# RK3399-AP register map
File version: 1
CPU: CA7 r0p1, little endian, MPU, FPU, I-cache, D-cache, VTOR, 4 interrupt priority bits, 32 interrupts
Registers are 32-bit, read-write, reset 0x0 unless marked. A register's access mark holds for its fields unless they carry their own. Offsets are from the block's base; [hi:lo] are bit positions; {n}, {i} and the like mark numbered series; 'fields as' and 'values as' point back to an identical list.

## PMU
Base 0xFF310000
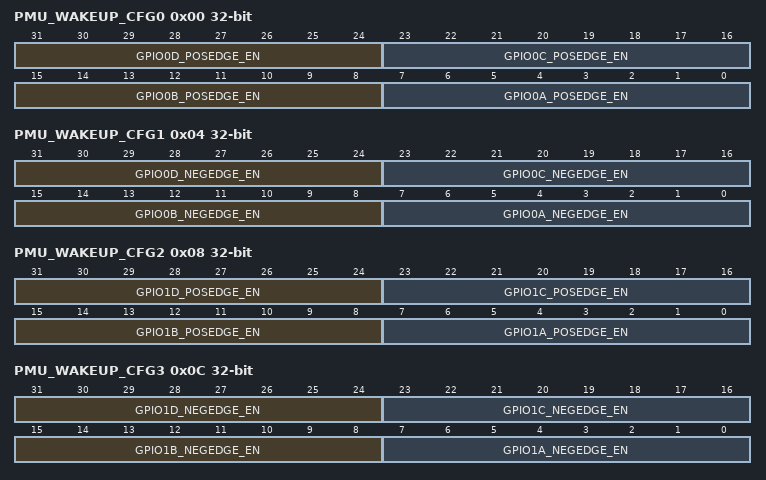
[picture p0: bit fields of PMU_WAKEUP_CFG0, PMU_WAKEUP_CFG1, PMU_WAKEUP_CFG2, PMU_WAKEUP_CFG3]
0x00 PMU_WAKEUP_CFG0 — pmu wakeup configure register 0
  [31:24] GPIO0D_POSEDGE_EN — gpio0d posedge pulse wakeup enable 0: disable 1: enable
  [23:16] GPIO0C_POSEDGE_EN — gpio0c posedge pulse wakeup enable 0: disable 1: enable
  [15:8] GPIO0B_POSEDGE_EN — gpio0b posedge pulse wakeup enable 0: disable 1: enable
  [7:0] GPIO0A_POSEDGE_EN — gpio0a posedge pulse wakeup enable 0: disable 1: enable
0x04 PMU_WAKEUP_CFG1 — pmu wakeup configure register 1
  [31:24] GPIO0D_NEGEDGE_EN — gpio0d negedge pulse wakeup enable 0: disable 1: enable
  [23:16] GPIO0C_NEGEDGE_EN — gpio0c negedge pulse wakeup enable 0: disable 1: enable
  [15:8] GPIO0B_NEGEDGE_EN — gpio0b negedge pulse wakeup enable 0: disable 1: enable
  [7:0] GPIO0A_NEGEDGE_EN — gpio0a negedge pulse wakeup enable 0: disable 1: enable
0x08 PMU_WAKEUP_CFG2 — pmu wakeup configure register 2
  [31:24] GPIO1D_POSEDGE_EN — gpio1d posedge pulse wakeup enable 0: disable 1: enable
  [23:16] GPIO1C_POSEDGE_EN — gpio1c posedge pulse wakeup enable 0: disable 1: enable
  [15:8] GPIO1B_POSEDGE_EN — gpio1b posedge pulse wakeup enable 0: disable 1: enable
  [7:0] GPIO1A_POSEDGE_EN — gpio1a posedge pulse wakeup enable 0: disable 1: enable
0x0C PMU_WAKEUP_CFG3 — pmu wakeup configure register 3
  [31:24] GPIO1D_NEGEDGE_EN — gpio1d negedge pulse wakeup enable 0: disable 1: enable
  [23:16] GPIO1C_NEGEDGE_EN — gpio1c negedge pulse wakeup enable 0: disable 1: enable
  [15:8] GPIO1B_NEGEDGE_EN — gpio1b negedge pulse wakeup enable 0: disable 1: enable
  [7:0] GPIO1A_NEGEDGE_EN — gpio1a negedge pulse wakeup enable 0: disable 1: enable
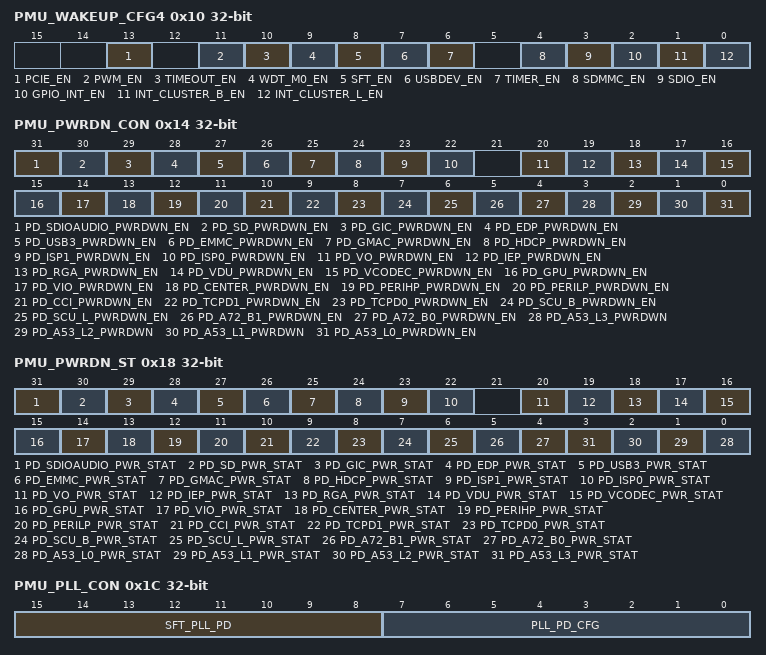
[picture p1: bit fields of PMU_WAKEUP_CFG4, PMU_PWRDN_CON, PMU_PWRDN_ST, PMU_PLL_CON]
0x10 PMU_WAKEUP_CFG4 — pmu wakeup configure register 4
  [13] PCIE_EN — pcie interrupt wakeup enable 0: disable 1: enable
  [11] PWM_EN — pwm interrupt wakeup enable 0: disable 1: enable
  [10] TIMEOUT_EN — pmu time out wakeup enable 0: disable 1: enable
  [9] WDT_M0_EN — m3 watch dog wakeup enable 0: disable 1: enable
  [8] SFT_EN — software wakeup enable 0: disable 1: enable
  [7] USBDEV_EN — usb device detect wakeup enable 0: disable 1: enable
  [6] TIMER_EN — timer wakeup enable 0: disable 1: enable
  [4] SDMMC_EN — sdmmc detect wakeup enable 0: disable 1: enable
  [3] SDIO_EN — sdio detect wakeup enable 0: disable 1: enable
  [2] GPIO_INT_EN — gpio interrupt wakeup enable 0: disable 1: enable
  [1] INT_CLUSTER_B_EN — cluster_b interrupt wakeup enable 0: disable 1: enable
  [0] INT_CLUSTER_L_EN — cluster_l interrupt wakeup enable 0: disable 1: enable
0x14 PMU_PWRDN_CON — pmu power down configure register
  [31] PD_SDIOAUDIO_PWRDWN_EN — pd_sdioaudio power down enable 0: disable 1: enable
  [30] PD_SD_PWRDWN_EN — pd_sd power down enable 0: disable 1: enable
  [29] PD_GIC_PWRDWN_EN — pd_gic power down enable 0: disable 1: enable
  [28] PD_EDP_PWRDWN_EN — pd_edp power down enable 0: disable 1: enable
  [27] PD_USB3_PWRDWN_EN — pd_usb3 power down enable 0: disable 1: enable
  [26] PD_EMMC_PWRDWN_EN — pd_emmc power down enable 0: disable 1: enable
  [25] PD_GMAC_PWRDWN_EN — pd_gmac power down enable 0: disable 1: enable
  [24] PD_HDCP_PWRDWN_EN — pd_hdcp power down enable 0: disable 1: enable
  [23] PD_ISP1_PWRDWN_EN — pd_isp1 power down enable 0: disable 1: enable
  [22] PD_ISP0_PWRDWN_EN — pd_isp0 power down enable 0: disable 1: enable
  [20] PD_VO_PWRDWN_EN — pd_vo power down enable 0: disable 1: enable
  [19] PD_IEP_PWRDWN_EN — pd_perihp power down enable 0: disable 1: enable
  [18] PD_RGA_PWRDWN_EN — pd_rga power down enable 0: disable 1: enable
  [17] PD_VDU_PWRDWN_EN — pd_vdu power down enable 0: disable 1: enable
  [16] PD_VCODEC_PWRDWN_EN — pd_perihp power down enable 0: disable 1: enable
  [15] PD_GPU_PWRDWN_EN — pd_gpu power down enable 0: disable 1: enable
  [14] PD_VIO_PWRDWN_EN — pd_vio power down enable 0: disable 1: enable
  [13] PD_CENTER_PWRDWN_EN — pd_center power down enable 0: disable 1: enable
  [12] PD_PERIHP_PWRDWN_EN — pd_perihp power down enable 0: disable 1: enable
  [11] PD_PERILP_PWRDWN_EN — pd_perilp power down enable 0: disable 1: enable
  [10] PD_CCI_PWRDWN_EN — pd_cci power down enable 0: disable 1: enable
  [9] PD_TCPD1_PWRDWN_EN — pd_tcpd1 power down enable 0: disable 1: enable
  [8] PD_TCPD0_PWRDWN_EN — pd_tcpd0 power down enable 0: disable 1: enable
  [7] PD_SCU_B_PWRDWN_EN — pd_scu_b power down enable 0: disable 1: enable
  [6] PD_SCU_L_PWRDWN_EN — pd_scu_l power down enable 0: disable 1: enable
  [5] PD_A72_B1_PWRDWN_EN — pd_a72_b0 power down enable 0: disable 1: enable
  [4] PD_A72_B0_PWRDWN_EN — pd_a72_b0 power down enable 0: disable 1: enable
  [3] PD_A53_L3_PWRDWN — pd_a53_l3 power down enable 0: disable 1: enable
  [2] PD_A53_L2_PWRDWN — pd_a53_l2 power down enable 0: disable 1: enable
  [1] PD_A53_L1_PWRDWN — pd_a53_l1 power down enable 0: disable 1: enable
  [0] PD_A53_L0_PWRDWN_EN — pd_a53_l0 power down enable 0: disable 1: enable
0x18 PMU_PWRDN_ST access per field — pmu power down status register
  [31] PD_SDIOAUDIO_PWR_STAT rw — pd_sdioaudio power state 0: powered up 1: powered down
  [30] PD_SD_PWR_STAT rw — pd_sd power state 0: powered up 1: powered down
  [29] PD_GIC_PWR_STAT rw — pd_gic power state 0: powered up 1: powered down
  [28] PD_EDP_PWR_STAT rw — pd_edp power state 0: powered up 1: powered down
  [27] PD_USB3_PWR_STAT rw — pd_usb3 power state 0: powered up 1: powered down
  [26] PD_EMMC_PWR_STAT rw — pd_emmc power state 0: powered up 1: powered down
  [25] PD_GMAC_PWR_STAT rw — pd_gmac power state 0: powered up 1: powered down
  [24] PD_HDCP_PWR_STAT rw — pd_hdcp power state 0: powered up 1: powered down
  [23] PD_ISP1_PWR_STAT rw — pd_isp1 power state 0: powered up 1: powered down
  [22] PD_ISP0_PWR_STAT rw — pd_isp0 power state 0: powered up 1: powered down
  [20] PD_VO_PWR_STAT rw — pd_vo power state 0: powered up 1: powered down
  [19] PD_IEP_PWR_STAT rw — pd_iep power state 0: powered up 1: powered down
  [18] PD_RGA_PWR_STAT rw — pd_rga power state 0: powered up 1: powered down
  [17] PD_VDU_PWR_STAT rw — pd_vdu power state 0: powered up 1: powered down
  [16] PD_VCODEC_PWR_STAT rw — pd_vcodec power state 0: powered up 1: powered down
  [15] PD_GPU_PWR_STAT rw — pd_gpu power state 0: powered up 1: powered down
  [14] PD_VIO_PWR_STAT rw — pd_vio power state 0: powered up 1: powered down
  [13] PD_CENTER_PWR_STAT rw — pd_center power state 0: powered up 1: powered down
  [12] PD_PERIHP_PWR_STAT rw — pd_peri power state 0: powered up 1: powered down
  [11] PD_PERILP_PWR_STAT rw — pd_bus power stat 0: powered up 1: powered down
  [10] PD_CCI_PWR_STAT rw — pd_core power state 0: powered up 1: powered down
  [9] PD_TCPD1_PWR_STAT rw — pd_tcpd1 power state 0: powered up 1: powered down
  [8] PD_TCPD0_PWR_STAT rw — pd_tcpd0 power state 0: powered up 1: powered down
  [7] PD_SCU_B_PWR_STAT ro — pd_scu_b power state 0: powered up 1: powered down
  [6] PD_SCU_L_PWR_STAT ro — pd_scu_l power state 0: powered up 1: powered down
  [5] PD_A72_B1_PWR_STAT ro — pd_a72_b1 power state 0: powered up 1: powered down
  [4] PD_A72_B0_PWR_STAT ro — pd_a72_b0 power state 0: powered up 1: powered down
  [n] PD_A53_L{n}_PWR_STAT ro (n=0..3) — pd_a53_l{n} power state 0: powered up 1: powered down
0x1C PMU_PLL_CON — PLL low power control register
  [15:8] SFT_PLL_PD — pll power down configured by sftware.
  [7:0] PLL_PD_CFG — pll power down configured by hardware
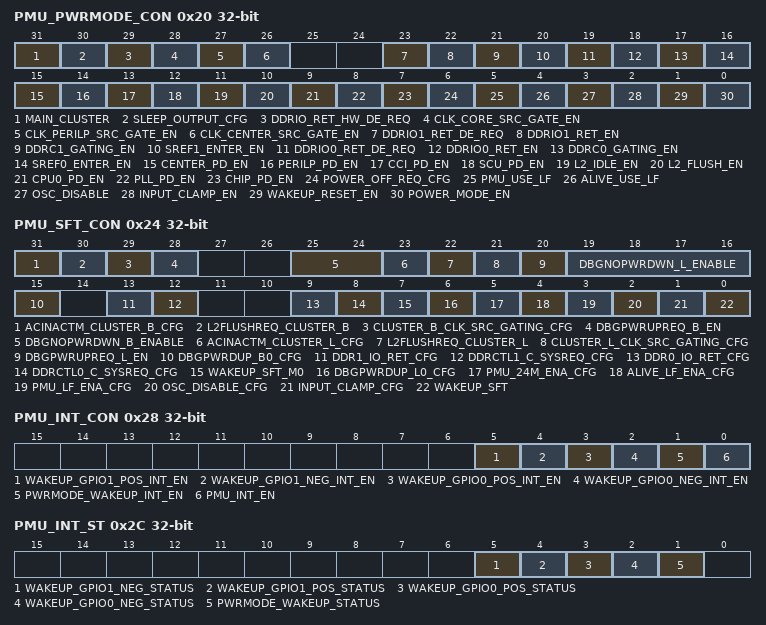
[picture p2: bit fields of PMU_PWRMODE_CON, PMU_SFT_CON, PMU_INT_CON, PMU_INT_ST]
0x20 PMU_PWRMODE_CON — pmu power mode configure register of common resource
  [31] MAIN_CLUSTER — use core big for main cluster. 0: core_l ; 1: core_b.
  [30] SLEEP_OUTPUT_CFG — output pmu_sleep instead of ap_pwroff to IO.
  [29] DDRIO_RET_HW_DE_REQ — hardware ddrio retention de-assert request
  [28] CLK_CORE_SRC_GATE_EN — cpu clock gate enable when in power mode 0: disable 1: enable
  [27] CLK_PERILP_SRC_GATE_EN — pd_perilp clock gate enable when in power mode 0: disable 1: enable
  [26] CLK_CENTER_SRC_GATE_EN — pd_center clock gate enable when in power mode 0: disable 1: enable
  [23] DDRIO1_RET_DE_REQ write-1-clears — ddrio1 retention de-assert request write one clear
  [22] DDRIO1_RET_EN — ddrio1 retention enable when in power mode 0: disable 1: enable
  [21] DDRC1_GATING_EN — ddr1 controller auto gating when in power mode 0: disable 1: enable
  [20] SREF1_ENTER_EN — ddr1 self_refresh by hardware when in power mode 0: disable 1: enable
  [19] DDRIO0_RET_DE_REQ write-1-clears — ddrio0 retention de-assert request write one clear
  [18] DDRIO0_RET_EN — ddrio0 retention enable when in power mode 0: disable 1: enable
  [17] DDRC0_GATING_EN — ddr0 controller auto gating when in power mode 0: disable 1: enable
  [16] SREF0_ENTER_EN — ddr0 self_refresh by hardware when in power mode 0: disable 1: enable
  [15] CENTER_PD_EN — power down pd_center when power mode 0: disable 1: enable
  [14] PERILP_PD_EN — power down pd_perilp when power mode 0: disable 1: enable
  [13] CCI_PD_EN — power down pd_cci when power mode 0: disable 1: enable
  [12] SCU_PD_EN — power down main cluster scu when in power mode 0: disable 1: enable
  [11] L2_IDLE_EN — wait l2 idle when in power mode 0: disable 1: enable
  [10] L2_FLUSH_EN — flush l2 by hardware when in power mode 0: disable 1: enable
  [9] CPU0_PD_EN — power down core0 of cluster_l in power mode 0: disable 1: enable
  [8] PLL_PD_EN — power down pll when in power mode 0: disable 1: enable
  [7] CHIP_PD_EN — chip power down enable 0: disable 1: enable
  [6] POWER_OFF_REQ_CFG — send power off request to PMIC when in power mode 0: disable 1: enable
  [5] PMU_USE_LF — pmu low frequency mode enable when in power mode 0: disable 1: enable
  [4] ALIVE_USE_LF — alive low frequency mode when in power mode 0: disable 1: enable
  [3] OSC_DISABLE — osc disable when in power mode 1: disable 0: enable
  [2] INPUT_CLAMP_EN — clamp vd_logic when in power mode 0: disable 1: enable
  [1] WAKEUP_RESET_EN — wakeup reset enable when in power mode 0: disable 1: enable
  [0] POWER_MODE_EN — enter power mode enable, will auto self-clear when in power mode 0: disable 1: enable
0x24 PMU_SFT_CON — pmu software configure register
  [31] ACINACTM_CLUSTER_B_CFG — acinactm indicate to cluster_b 0: acinactm to cluster_b is 0 1: acinactm to cluster_b is 1
  [30] L2FLUSHREQ_CLUSTER_B — send l2 flush request to cluster_l by software 0: disable 1: enable
  [29] CLUSTER_B_CLK_SRC_GATING_CFG — cluster_b clock source gating configure 0: disable 1: enable
  [28] DBGPWRUPREQ_B_EN — dbg powered up request function of cluster_b enable 0: disable 1: enable
  [25:24] DBGNOPWRDWN_B_ENABLE — dbgnopowerdown function of cluster_b enable 0: disable 1: enable
  [23] ACINACTM_CLUSTER_L_CFG — acinactm indicate to cluster_l 0: acinactm to cluster_l is 0 1: acinactm to cluster_l is 1
  [22] L2FLUSHREQ_CLUSTER_L — send l2 flush request to cluster_l by software 0: disable 1: enable
  [21] CLUSTER_L_CLK_SRC_GATING_CFG — cluster_l clock source gating configure 0: disable 1: enable
  [20] DBGPWRUPREQ_L_EN — dbg powered up request function of cluster_l enable 0: disable 1: enable
  [19:16] DBGNOPWRDWN_L_ENABLE — dbgnopowerdown function of cluster_l enable 0: disable 1: enable
  [15] DBGPWRDUP_B0_CFG — dbg powered up of pd_a72_b0 enable when in power mode 0: disable 1: enable
  [13] DDR1_IO_RET_CFG — ddr1 io retention configure by software 0: disable 1: enable
  [12] DDRCTL1_C_SYSREQ_CFG — ddrctl1 idle request configure 0: disable 1: enable
  [9] DDR0_IO_RET_CFG — ddr0 io retention configure by software 0: disable 1: enable
  [8] DDRCTL0_C_SYSREQ_CFG — ddrctl idle request configure 0: disable 1: enable
  [7] WAKEUP_SFT_M0 — m0 configure this bit to wakeup PMU state machine.
  [6] DBGPWRDUP_L0_CFG — dbg powered up of pd_a53_l0 enable when in power mode 0: disable 1: enable
  [5] PMU_24M_ENA_CFG — configure PD_PMU use 24M clock
  [4] ALIVE_LF_ENA_CFG — pd_alive low frequency mode configure by software 0: disable 1: enable
  [3] PMU_LF_ENA_CFG — pd_pmu low frequency mode configure by software 0: disable 1: enable
  [2] OSC_DISABLE_CFG — osc disable configure by software 1: disable osc 0: enable psc
  [1] INPUT_CLAMP_CFG — software control of input clamp signal
  [0] WAKEUP_SFT — software wakeup request bit A 0 to 1 pulse posedge will wakeup pmu when in low power mode
0x28 PMU_INT_CON — pmu interrupt configure register
  [5] WAKEUP_GPIO1_POS_INT_EN — gpio1 posedge wakeup interrupt enable 0: disable 1: enable
  [4] WAKEUP_GPIO1_NEG_INT_EN — gpio1 negedge wakeup interrupt enable 0: disable 1: enable
  [3] WAKEUP_GPIO0_POS_INT_EN — gpio posedge wakeup interrupt enable 0: disable 1: enable
  [2] WAKEUP_GPIO0_NEG_INT_EN — gpio0 negedge wakeup interrupt enable 0: disable 1: enable
  [1] PWRMODE_WAKEUP_INT_EN — power mode wakeup interrupt enable 0: disable 1: enable
  [0] PMU_INT_EN — global interrupt enable 0: disable 1: enable
0x2C PMU_INT_ST — pmu interrupt status register
  [5] WAKEUP_GPIO1_NEG_STATUS — gpio1 negedge pulse wakeup status 0: not wakeup by gpio1 negedge pulse 1: wakeup by gpio1 negedge pulse
  [4] WAKEUP_GPIO1_POS_STATUS — gpio1 posedge pulse wakeup status 0: not wakeup by gpio1 posedge pulse 1: wakeup by gpio1 posedge pulse
  [3] WAKEUP_GPIO0_POS_STATUS — gpio0 posedge pulse wakeup status 0: not wakeup by gpio0 posedge pulse 1: wakeup by gpio0 posedge pulse
  [2] WAKEUP_GPIO0_NEG_STATUS — gpio0 negedge pulse wakeup status 0: not wakeup by gpio negedge pulse 1: wakeup by gpio negedge pulse
  [1] PWRMODE_WAKEUP_STATUS — power mode wakeup status 0: not wakeup from power mode 1: wakeup from power mode
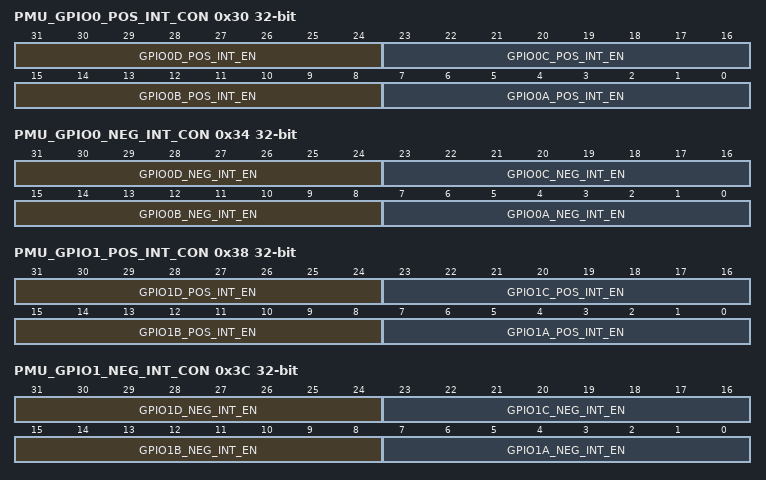
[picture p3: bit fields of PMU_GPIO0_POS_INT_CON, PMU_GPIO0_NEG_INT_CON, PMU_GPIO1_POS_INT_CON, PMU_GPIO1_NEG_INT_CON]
0x30 PMU_GPIO0_POS_INT_CON — pmu gpio0 posedge interrupt configure register
  [31:24] GPIO0D_POS_INT_EN — gpio0d posedge pulse interrupt enable 0: disable 1: enable
  [23:16] GPIO0C_POS_INT_EN — gpio0c posedge pulse interrupt enable 0: disable 1: enable
  [15:8] GPIO0B_POS_INT_EN — gpio0b posedge pulse interrupt enable 0: disable 1: enable
  [7:0] GPIO0A_POS_INT_EN — gpio0a posedge pulse interrupt enable 0: disable 1: enable
0x34 PMU_GPIO0_NEG_INT_CON — pmu gpio0 negedge interrupt configure register
  [31:24] GPIO0D_NEG_INT_EN — gpio0d negedge pulse interrupt enable 0: disable 1: enable
  [23:16] GPIO0C_NEG_INT_EN — gpio0c negedge pulse interrupt enable 0: disable 1: enable
  [15:8] GPIO0B_NEG_INT_EN — gpio0b negedge pulse interrupt enable 0: disable 1: enable
  [7:0] GPIO0A_NEG_INT_EN — gpio0a negedge pulse interrupt enable 0: disable 1: enable
0x38 PMU_GPIO1_POS_INT_CON — pmu gpio1 posedge interrupt configure register
  [31:24] GPIO1D_POS_INT_EN — gpio1d posedge pulse interrupt enable 0: disable 1: enable
  [23:16] GPIO1C_POS_INT_EN — gpio1c posedge pulse interrupt enable 0: disable 1: enable
  [15:8] GPIO1B_POS_INT_EN — gpio1b posedge pulse interrupt enable 0: disable 1: enable
  [7:0] GPIO1A_POS_INT_EN — gpio1a posedge pulse interrupt enable 0: disable 1: enable
0x3C PMU_GPIO1_NEG_INT_CON — pmu gpio1 negedge interrupt configure register
  [31:24] GPIO1D_NEG_INT_EN — gpio1d negedge pulse interrupt enable 0: disable 1: enable
  [23:16] GPIO1C_NEG_INT_EN — gpio1c negedge pulse interrupt enable 0: disable 1: enable
  [15:8] GPIO1B_NEG_INT_EN — gpio1b negedge pulse interrupt enable 0: disable 1: enable
  [7:0] GPIO1A_NEG_INT_EN — gpio1a negedge pulse interrupt enable 0: disable 1: enable
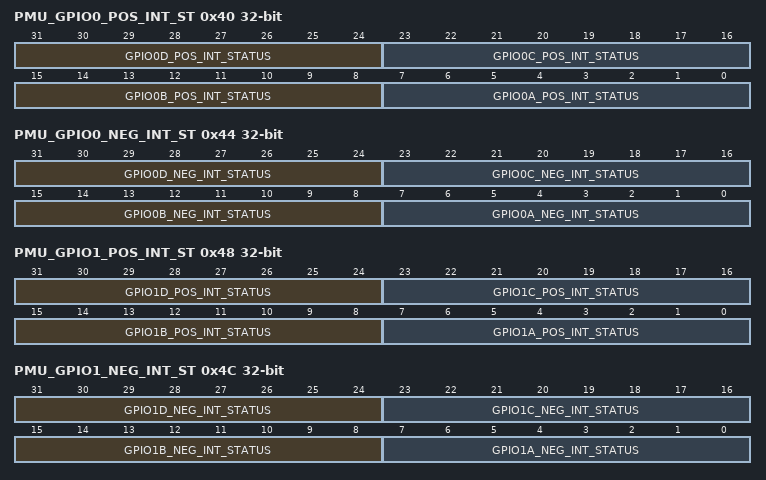
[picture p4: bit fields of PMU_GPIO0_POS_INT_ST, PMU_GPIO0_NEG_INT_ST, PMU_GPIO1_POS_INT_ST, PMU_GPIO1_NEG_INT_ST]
0x40 PMU_GPIO0_POS_INT_ST — pmu gpio0 posedge interrupt status register
  [31:24] GPIO0D_POS_INT_STATUS — gpio0d posedge pulse interrupt status 0: not wakeup by gpio0d posedge pulse 1: wakeup by gpio0d posedge pulse
  [23:16] GPIO0C_POS_INT_STATUS — gpio0c posedge pulse interrupt status 0: not wakeup by gpio0c posedge pulse 1: wakeup by gpio0c posedge pulse
  [15:8] GPIO0B_POS_INT_STATUS — gpio0b posedge pulse interrupt status 0: not wakeup by gpio0b posedge pulse 1: wakeup by gpio0b posedge pulse
  [7:0] GPIO0A_POS_INT_STATUS — gpio0a posedge pulse interrupt status 0: not wakeup by gpio0a posedge pulse 1: wakeup by gpio0a posedge pulse
0x44 PMU_GPIO0_NEG_INT_ST — pmu gpio0 negedge interrupt status register
  [31:24] GPIO0D_NEG_INT_STATUS — gpio0d negedge pulse interrupt status 0: not wakeup by gpio0d negedge pulse 1: wakeup by gpio0d negedge pulse
  [23:16] GPIO0C_NEG_INT_STATUS — gpio0c negedge pulse interrupt status 0: not wakeup by gpio0c negedge pulse 1: wakeup by gpio0c negedge pulse
  [15:8] GPIO0B_NEG_INT_STATUS — gpio0b negedge pulse interrupt status 0: not wakeup by gpio0b negedge pulse 1: wakeup by gpio0b negedge pulse
  [7:0] GPIO0A_NEG_INT_STATUS — gpio0a negedge pulse interrupt status 0: not wakeup by gpio0a negedge pulse 1: wakeup by gpio0a negedge pulse
0x48 PMU_GPIO1_POS_INT_ST — pmu gpio1 posedge interrupt status register
  [31:24] GPIO1D_POS_INT_STATUS — gpio1d posedge pulse interrupt status 0: not wakeup by gpio1d posedge pulse 1: wakeup by gpio1d posedge pulse
  [23:16] GPIO1C_POS_INT_STATUS — gpio1c posedge pulse interrupt status 0: not wakeup by gpio1c posedge pulse 1: wakeup by gpio1c posedge pulse
  [15:8] GPIO1B_POS_INT_STATUS — gpio1b posedge pulse interrupt status 0: not wakeup by gpio1b posedge pulse 1: wakeup by gpio1b posedge pulse
  [7:0] GPIO1A_POS_INT_STATUS — gpio1a posedge pulse interrupt status 0: not wakeup by gpio1a posedge pulse 1: wakeup by gpio1a posedge pulse
0x4C PMU_GPIO1_NEG_INT_ST — pmu gpio1 negedge interrupt status register
  [31:24] GPIO1D_NEG_INT_STATUS — gpio1d negedge pulse interrupt status 0: not wakeup by gpio1d negedge pulse 1: wakeup by gpio1d negedge pulse
  [23:16] GPIO1C_NEG_INT_STATUS — gpio1c negedge pulse interrupt status 0: not wakeup by gpio1c negedge pulse 1: wakeup by gpio1c negedge pulse
  [15:8] GPIO1B_NEG_INT_STATUS — gpio1b negedge pulse interrupt status 0: not wakeup by gpio1b negedge pulse 1: wakeup by gpio1b negedge pulse
  [7:0] GPIO1A_NEG_INT_STATUS — gpio1a negedge pulse interrupt status 0: not wakeup by gpio1a negedge pulse 1: wakeup by gpio1a negedge pulse
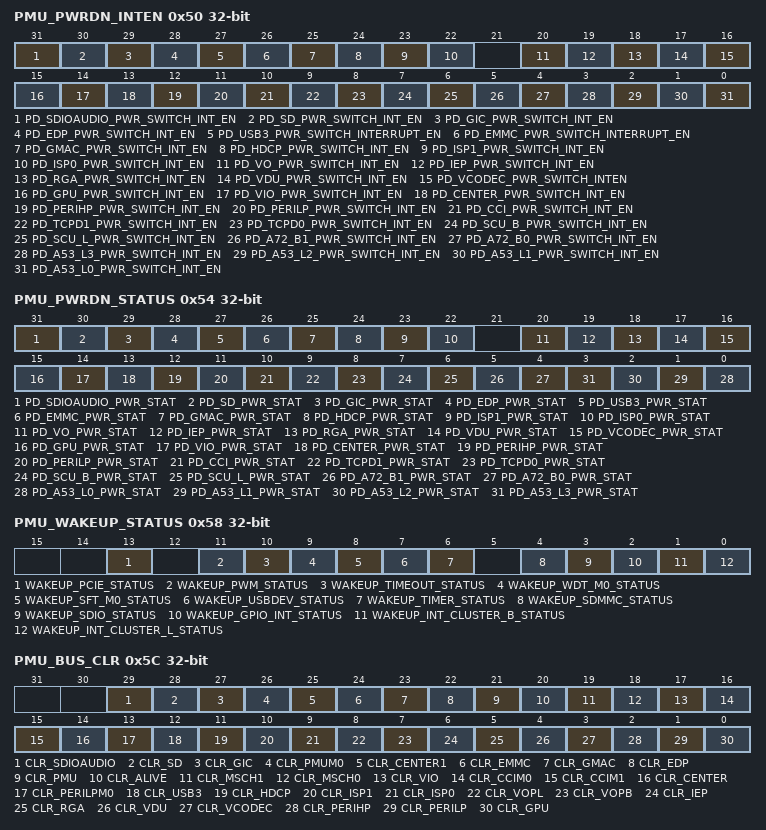
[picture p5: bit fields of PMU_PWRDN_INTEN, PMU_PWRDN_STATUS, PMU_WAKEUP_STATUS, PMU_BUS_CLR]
0x50 PMU_PWRDN_INTEN — pmu power down interrupt enable register/pmu power down configure register
  [31] PD_SDIOAUDIO_PWR_SWITCH_INT_EN — pd_sdioaudio power switch interrupt enable 0: disable 1: enable
  [30] PD_SD_PWR_SWITCH_INT_EN — pd_sd power switch interrupt enable 0: disable 1: enable
  [29] PD_GIC_PWR_SWITCH_INT_EN — pd_gic power switch interrupt enable 0: disable 1: enable
  [28] PD_EDP_PWR_SWITCH_INT_EN — pd_edp power switch interrupt enable 0: disable 1: enable
  [27] PD_USB3_PWR_SWITCH_INTERRUPT_EN — pd_usb3 power switch interrupt enable 0: disable 1: enable
  [26] PD_EMMC_PWR_SWITCH_INTERRUPT_EN — pd_emmc power switch interrupt enable 0: disable 1: enable
  [25] PD_GMAC_PWR_SWITCH_INT_EN — pd_gmac power switch interrupt enable 0: disable 1: enable
  [24] PD_HDCP_PWR_SWITCH_INT_EN — pd_hdcp power switch interrupt enable 0: disable 1: enable
  [23] PD_ISP1_PWR_SWITCH_INT_EN — pd_isp1 power switch interrupt enable 0: disable 1: enable
  [22] PD_ISP0_PWR_SWITCH_INT_EN — pd_isp0 power switch interrupt enable 0: disable 1: enable
  [20] PD_VO_PWR_SWITCH_INT_EN — pd_vo power switch interrupt enable 0: disable 1: enable
  [19] PD_IEP_PWR_SWITCH_INT_EN — pd_perihp power switch interrupt enable 0: disable 1: enable
  [18] PD_RGA_PWR_SWITCH_INT_EN — pd_rga power switch interrupt enable 0: disable 1: enable
  [17] PD_VDU_PWR_SWITCH_INT_EN — pd_vdu power switch interrupt enable 0: disable 1: enable
  [16] PD_VCODEC_PWR_SWITCH_INTEN — pd_perihp power switch interrupt enable 0: disable 1: enable
  [15] PD_GPU_PWR_SWITCH_INT_EN — pd_gpu power interrupt enable 0: disable 1: enable
  [14] PD_VIO_PWR_SWITCH_INT_EN — pd_vio power switch interrupt enable 0: disable 1: enable
  [13] PD_CENTER_PWR_SWITCH_INT_EN — pd_center power switch interrupt enable 0: disable 1: enable
  [12] PD_PERIHP_PWR_SWITCH_INT_EN — pd_perihp power switch interrupt enable 0: disable 1: enable
  [11] PD_PERILP_PWR_SWITCH_INT_EN — pd_perilp power switch interrupt enable 0: disable 1: enable
  [10] PD_CCI_PWR_SWITCH_INT_EN — pd_cci power switch interrupt enable 0: disable 1: enable
  [9] PD_TCPD1_PWR_SWITCH_INT_EN — pd_tcpd1 power switch interrupt enable 0: disable 1: enable
  [8] PD_TCPD0_PWR_SWITCH_INT_EN — pd_tcpd0 power switch interrupt enable 0: disable 1: enable
  [7] PD_SCU_B_PWR_SWITCH_INT_EN — pd_scu_b power switch interrupt enable 0: disable 1: enable
  [6] PD_SCU_L_PWR_SWITCH_INT_EN — pd_scu_l power switch interrupt enable 0: disable 1: enable
  [5] PD_A72_B1_PWR_SWITCH_INT_EN — pd_a72_b1 power switch interrupt enable 0: disable 1: enable
  [4] PD_A72_B0_PWR_SWITCH_INT_EN — pd_a72_b0 power enable 0: disable 1: enable
  [3] PD_A53_L3_PWR_SWITCH_INT_EN — pd_a53_l3 power switch int enable 0: disable 1: enable
  [2] PD_A53_L2_PWR_SWITCH_INT_EN — pd_a53_l2 power switch interrupt enable 0: disable 1: enable
  [1] PD_A53_L1_PWR_SWITCH_INT_EN — pd_a53_l1 power switch interrupt enable 0: disable 1: enable
  [0] PD_A53_L0_PWR_SWITCH_INT_EN — pd_a53_l0 power switch interrupt enable 0: disable 1: enable
0x54 PMU_PWRDN_STATUS — pmu power down interrupt status register/pmu power down status register
  [31] PD_SDIOAUDIO_PWR_STAT write-1-clears — pd_sdioaudio power state 0: powered up 1: powered down
  [30] PD_SD_PWR_STAT write-1-clears — pd_sd power state 0: powered up 1: powered down
  [29] PD_GIC_PWR_STAT write-1-clears — pd_gic power state 0: powered up 1: powered down
  [28] PD_EDP_PWR_STAT write-1-clears — pd_edp power state 0: powered up 1: powered down
  [27] PD_USB3_PWR_STAT write-1-clears — pd_usb3 power state 0: powered up 1: powered down
  [26] PD_EMMC_PWR_STAT write-1-clears — pd_emmc power state 0: powered up 1: powered down
  [25] PD_GMAC_PWR_STAT write-1-clears — pd_gmac power state 0: powered up 1: powered down
  [24] PD_HDCP_PWR_STAT write-1-clears — pd_hdcp power state 0: powered up 1: powered down
  [23] PD_ISP1_PWR_STAT write-1-clears — pd_isp1 power state 0: powered up 1: powered down
  [22] PD_ISP0_PWR_STAT write-1-clears — pd_isp0 power state 0: powered up 1: powered down
  [20] PD_VO_PWR_STAT write-1-clears — pd_vo power state 0: powered up 1: powered down
  [19] PD_IEP_PWR_STAT write-1-clears — pd_iep power state 0: powered up 1: powered down
  [18] PD_RGA_PWR_STAT write-1-clears — pd_rga power state 0: powered up 1: powered down
  [17] PD_VDU_PWR_STAT write-1-clears — pd_vdu power state 0: powered up 1: powered down
  [16] PD_VCODEC_PWR_STAT write-1-clears — pd_vcodec power state 0: powered up 1: powered down
  [15] PD_GPU_PWR_STAT write-1-clears — pd_gpu power state 0: powered up 1: powered down
  [14] PD_VIO_PWR_STAT write-1-clears — pd_vio power state 0: powered up 1: powered down
  [13] PD_CENTER_PWR_STAT write-1-clears — pd_center power state 0: powered up 1: powered down
  [12] PD_PERIHP_PWR_STAT write-1-clears — pd_perihp power state 0: powered up 1: powered down
  [11] PD_PERILP_PWR_STAT write-1-clears — pd_perilp power stat 0: powered up 1: powered down
  [10] PD_CCI_PWR_STAT write-1-clears — pd_core power state 0: powered up 1: powered down
  [9] PD_TCPD1_PWR_STAT write-1-clears — pd_tcpd1 power state 0: powered up 1: powered down
  [8] PD_TCPD0_PWR_STAT write-1-clears — pd_tcpd0 power state 0: powered up 1: powered down
  [7] PD_SCU_B_PWR_STAT write-1-clears — pd_scu_b power state 0: powered up 1: powered down
  [6] PD_SCU_L_PWR_STAT write-1-clears — pd_scu_l power state 0: powered up 1: powered down
  [5] PD_A72_B1_PWR_STAT write-1-clears — pd_a72_b1 power state 0: powered up 1: powered down
  [4] PD_A72_B0_PWR_STAT write-1-clears — pd_a72_b0 power state 0: powered up 1: powered down
  [n] PD_A53_L{n}_PWR_STAT write-1-clears (n=0..3) — pd_a53_l{n} power state 0: powered up 1: powered down
0x58 PMU_WAKEUP_STATUS — pmu interrupt wakeup status register/pmu interrupt status register
  [13] WAKEUP_PCIE_STATUS — pcie wakeup status 0: not wakeup by pcie 1: wakeup by pcie
  [11] WAKEUP_PWM_STATUS — pwm wakeup status 0: not wakeup by pwm 1: wakeup by pwm
  [10] WAKEUP_TIMEOUT_STATUS — timeout wakeup status 0: not wakeup by timeout 1: wakeup by timeout
  [9] WAKEUP_WDT_M0_STATUS — m0 wdt interrupt wakeup status 0: not wakeup by m0 wdt interrupt 1: wakeup by m0 wdt interrupt
  [8] WAKEUP_SFT_M0_STATUS — m0 software control wakeup status 0: not wakeup by software 1: wakeup by software
  [7] WAKEUP_USBDEV_STATUS — usbdev detect wakeup status 0: not wakeup by usbdev detect 1: wakeup by usbdev detect
  [6] WAKEUP_TIMER_STATUS — timer wakeup status 0: not wakeup by timer 1: wakeup by timer
  [4] WAKEUP_SDMMC_STATUS — sdmmc wakeup status 0: not wakeup by sdmmc detect 1: wakeup by sdmmc detect
  [3] WAKEUP_SDIO_STATUS — sdio wakeup status 0: not wakeup by sdio detect 1: wakeup by sdio detect
  [2] WAKEUP_GPIO_INT_STATUS — gpio interrupt wakeup status 0: not wakeup by gpio int 1: wakeup by gpio int
  [1] WAKEUP_INT_CLUSTER_B_STATUS — cluster_b interrupt wakeup status 0: not wakeup by interrupt cluster_b 1: wakeup by interrupt cluster_b
  [0] WAKEUP_INT_CLUSTER_L_STATUS — cluster_l interrupt wakeup status 0: not wakeup by interrupt cluster_l 1: wakeup by interrupt cluster_l
0x5C PMU_BUS_CLR — pmu bus clear register
  [29] CLR_SDIOAUDIO — send idle request to sdioaudio low power interface 0: disable 1: enable
  [28] CLR_SD — send idle request to sd low power interface 0: disable 1: enable
  [27] CLR_GIC — send idle request to gic low power interface 0: disable 1: enable
  [26] CLR_PMUM0 — send idle request to pmu m0 low power interface 0: disable 1: enable
  [25] CLR_CENTER1 — send idle request to center1 low power interface 0: disable 1: enable
  [24] CLR_EMMC — send idle request to emmc low power interface 0: disable 1: enable
  [23] CLR_GMAC — send idle request to gmac low power interface 0: disable 1: enable
  [22] CLR_EDP — send idle request to edp low power interface 0: disable 1: enable
  [21] CLR_PMU — send idle request to pmu low power interface 0: disable 1: enable
  [20] CLR_ALIVE — send idle request to alive low power interface 0: disable 1: enable
  [19] CLR_MSCH1 — send idle request to msch1 low power interface 0: disable 1: enable
  [18] CLR_MSCH0 — send idle request to msch0 low power interface 0: disable 1: enable
  [17] CLR_VIO — send idle request to vio low power interface 0: disable 1: enable
  [16] CLR_CCIM0 — send idle request to ccim0 low power interface 0: disable 1: enable
  [15] CLR_CCIM1 — send idle request to ccim1 low power interface 0: disable 1: enable
  [14] CLR_CENTER — send idle request to center niu 0: disable 1: enable
  [13] CLR_PERILPM0 — send idle request to perilp m0 niu 0: disable 1: enable
  [12] CLR_USB3 — send idle request to usb3 niu 0: disable 1: enable
  [11] CLR_HDCP — send idle request to hdcp niu 0: disable 1: enable
  [10] CLR_ISP1 — send idle request to isp1 niu 0: disable 1: enable
  [9] CLR_ISP0 — send idle request to isp0 niu 0: disable 1: enable
  [8] CLR_VOPL — send idle request to vopl niu 0: disable 1: enable
  [7] CLR_VOPB — send idle request to vopb niu 0: disable 1: enable
  [6] CLR_IEP — send idle request to iep niu 0: disable 1: enable
  [5] CLR_RGA — send idle request to rga niu 0: disable 1: enable
  [4] CLR_VDU — send idle request to vdu niu 0: disable 1: enable
  [3] CLR_VCODEC — send idle request to vcodec niu 0: disable 1: enable
  [2] CLR_PERIHP — send idle request to perihp niu 0: disable 1: enable
  [1] CLR_PERILP — send idle request to perilp niu 0: disable 1: enable
  [0] CLR_GPU — send idle request to gpu niu 0: disable 1: enable
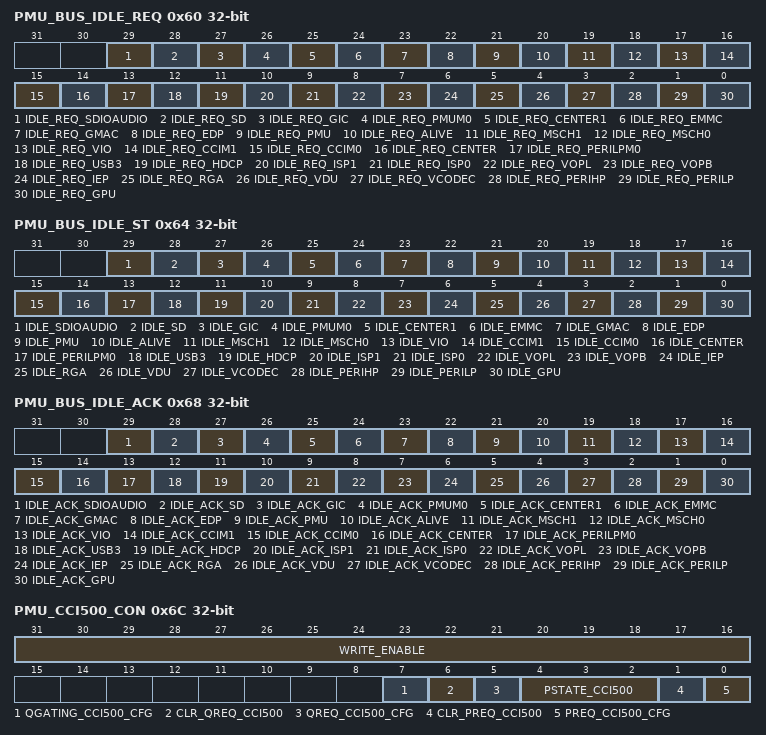
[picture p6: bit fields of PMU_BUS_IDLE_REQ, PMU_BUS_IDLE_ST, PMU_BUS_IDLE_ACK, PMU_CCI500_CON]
0x60 PMU_BUS_IDLE_REQ — pmu bus idle request register
  [29] IDLE_REQ_SDIOAUDIO — send idle request to sdioaudio low power interface 0: disable 1: enable
  [28] IDLE_REQ_SD — send idle request to sd low power interface 0: disable 1: enable
  [27] IDLE_REQ_GIC — send idle request to gic low power interface 0: disable 1: enable
  [26] IDLE_REQ_PMUM0 — send idle request to pmu m0 low power interface 0: disable 1: enable
  [25] IDLE_REQ_CENTER1 — send idle request to center1 low power interface 0: disable 1: enable
  [24] IDLE_REQ_EMMC — send idle request to emmc low power interface 0: disable 1: enable
  [23] IDLE_REQ_GMAC — send idle request to gmac low power interface 0: disable 1: enable
  [22] IDLE_REQ_EDP — send idle request to edp low power interface 0: disable 1: enable
  [21] IDLE_REQ_PMU — send idle request to pmu low power interface 0: disable 1: enable
  [20] IDLE_REQ_ALIVE — send idle request to alive low power interface 0: disable 1: enable
  [19] IDLE_REQ_MSCH1 — send idle request to msch1 low power interface 0: disable 1: enable
  [18] IDLE_REQ_MSCH0 — send idle request to msch0 low power interface 0: disable 1: enable
  [17] IDLE_REQ_VIO — send idle request to vio low power interface 0: disable 1: enable
  [16] IDLE_REQ_CCIM1 — send idle request to ccim1 low power interface 0: disable 1: enable
  [15] IDLE_REQ_CCIM0 — send idle request to ccim0 low power interface 0: disable 1: enable
  [14] IDLE_REQ_CENTER — send idle request to center niu 0: disable 1: enable
  [13] IDLE_REQ_PERILPM0 — send idle request to perilp m0 niu 0: disable 1: enable
  [12] IDLE_REQ_USB3 — send idle request to usb3 niu 0: disable 1: enable
  [11] IDLE_REQ_HDCP — send idle request to hdcp niu 0: disable 1: enable
  [10] IDLE_REQ_ISP1 — send idle request to isp1 niu 0: disable 1: enable
  [9] IDLE_REQ_ISP0 — send idle request to isp0 niu 0: disable 1: enable
  [8] IDLE_REQ_VOPL — send idle request to vopl niu 0: disable 1: enable
  [7] IDLE_REQ_VOPB — send idle request to vopb niu 0: disable 1: enable
  [6] IDLE_REQ_IEP — send idle request to iep niu 0: disable 1: enable
  [5] IDLE_REQ_RGA — send idle request to rga niu 0: disable 1: enable
  [4] IDLE_REQ_VDU — send idle request to vdu niu 0: disable 1: enable
  [3] IDLE_REQ_VCODEC — send idle request to vcodec niu 0: disable 1: enable
  [2] IDLE_REQ_PERIHP — send idle request to perihp niu 0: disable 1: enable
  [1] IDLE_REQ_PERILP — send idle request to perilp niu 0: disable 1: enable
  [0] IDLE_REQ_GPU — send idle request to gpu niu 0: disable 1: enable
0x64 PMU_BUS_IDLE_ST ro — pmu bus idle status register
  [29] IDLE_SDIOAUDIO — send idle request to sdioaudio low power interface 0: disable 1: enable
  [28] IDLE_SD — send idle request to sd low power interface 0: disable 1: enable
  [27] IDLE_GIC — idle status of gic niu 0: idle status of niu is 0 1: idle status of niu is 1
  [26] IDLE_PMUM0 — idle status of pmu m0 niu 0: idle status of niu is 0 1: idle status of niu is 1
  [25] IDLE_CENTER1 — idle status of center1 niu 0: idle status of niu is 0 1: idle status of niu is 1
  [24] IDLE_EMMC — idle status of emmc niu 0: idle status of niu is 0 1: idle status of niu is 1
  [23] IDLE_GMAC — idle status of gmac niu 0: idle status of niu is 0 1: idle status of niu is 1
  [22] IDLE_EDP — idle status of edp niu 0: idle status of niu is 0 1: idle status of niu is 1
  [21] IDLE_PMU — idle status of pmu niu 0: idle status of niu is 0 1: idle status of niu is 1
  [20] IDLE_ALIVE — idle status of alive niu 0: idle status of niu is 0 1: idle status of niu is 1
  [19] IDLE_MSCH1 — idle status of msch1 niu 0: idle status of niu is 0 1: idle status of niu is 1
  [18] IDLE_MSCH0 — idle status of msch0 niu 0: idle status of niu is 0 1: idle status of niu is 1
  [17] IDLE_VIO — idle status of vio niu 0: idle status of niu is 0 1: idle status of niu is 1
  [16] IDLE_CCIM1 — idle status of ccim1 niu 0: idle status of niu is 0 1: idle status of niu is 1
  [15] IDLE_CCIM0 — idle status of ccim0 niu 0: idle status of niu is 0 1: idle status of niu is 1
  [14] IDLE_CENTER — idle status of center niu 0: idle status of niu is 0 1: idle status of niu is 1
  [13] IDLE_PERILPM0 — idle status of perilpm0 niu 0: idle status of niu is 0 1: idle status of niu is 1
  [12] IDLE_USB3 — idle status of usb3 niu 0: idle status of niu is 0 1: idle status of niu is 1
  [11] IDLE_HDCP — idle status of hdcp niu 0: idle status of niu is 0 1: idle status of niu is 1
  [10] IDLE_ISP1 — idle status of isp1 niu 0: idle status of niu is 0 1: idle status of niu is 1
  [9] IDLE_ISP0 — idle status of isp0 niu 0: idle status of niu is 0 1: idle status of niu is 1
  [8] IDLE_VOPL — idle status of vopl niu 0: idle status of niu is 0 1: idle status of niu is 1
  [7] IDLE_VOPB — idle status of vopb niu 0: idle status of niu is 0 1: idle status of niu is 1
  [6] IDLE_IEP — idle status of iep niu 0: idle status of niu is 0 1: idle status of niu is 1
  [5] IDLE_RGA — idle status of rga niu 0: idle status of niu is 0 1: idle status of niu is 1
  [4] IDLE_VDU — idle status of vdu niu 0: idle status of niu is 0 1: idle status of niu is 1
  [3] IDLE_VCODEC — idle status of vcodec niu 0: idle status of niu is 0 1: idle status of niu is 1
  [2] IDLE_PERIHP — idle status of perihp niu 0: idle status of niu is 0 1: idle status of niu is 1
  [1] IDLE_PERILP — idle status of perilp niu 0: idle status of niu is 0 1: idle status of niu is 1
  [0] IDLE_GPU — idle status of gpu niu 0: idle status of gpu_niu is 0 1: idle status of gpu_niu is 1
0x68 PMU_BUS_IDLE_ACK ro — pmu bus idle ack status register
  [29] IDLE_ACK_SDIOAUDIO — idle acknowledge status from sdioaudio niu 0: idle acknowledge status of niu is 0 1: idle acknowledge status of niu is 1
  [28] IDLE_ACK_SD — idle acknowledge status from sd niu 0: idle acknowledge status of niu is 0 1: idle acknowledge status of niu is 1
  [27] IDLE_ACK_GIC — idle acknowledge status from gic niu 0: idle acknowledge status of niu is 0 1: idle acknowledge status of niu is 1
  [26] IDLE_ACK_PMUM0 — idle acknowledge status from pmu m0 niu 0: idle acknowledge status of niu is 0 1: idle acknowledge status of niu is 1
  [25] IDLE_ACK_CENTER1 — idle acknowledge status from center1 niu 0: idle acknowledge status of niu is 0 1: idle acknowledge status of niu is 1
  [24] IDLE_ACK_EMMC — idle acknowledge status from emmc niu 0: idle acknowledge status of niu is 0 1: idle acknowledge status of niu is 1
  [23] IDLE_ACK_GMAC — idle acknowledge status from gmac niu 0: idle acknowledge status of niu is 0 1: idle acknowledge status of niu is 1
  [22] IDLE_ACK_EDP — idle acknowledge status from edp niu 0: idle acknowledge status of niu is 0 1: idle acknowledge status of niu is 1
  [21] IDLE_ACK_PMU — idle acknowledge status from pmu niu 0: idle acknowledge status of niu is 0 1: idle acknowledge status of niu is 1
  [20] IDLE_ACK_ALIVE — idle acknowledge status from alive niu 0: idle acknowledge status of niu is 0 1: idle acknowledge status of niu is 1
  [19] IDLE_ACK_MSCH1 — idle acknowledge status from msch1 niu 0: idle acknowledge status of niu is 0 1: idle acknowledge status of niu is 1
  [18] IDLE_ACK_MSCH0 — idle acknowledge status from msch0 niu 0: idle acknowledge status of niu is 0 1: idle acknowledge status of niu is 1
  [17] IDLE_ACK_VIO — idle acknowledge status from vio niu 0: idle acknowledge status of niu is 0 1: idle acknowledge status of niu is 1
  [16] IDLE_ACK_CCIM1 — idle acknowledge status from ccim1 niu 0: idle acknowledge status of niu is 0 1: idle acknowledge status of niu is 1
  [15] IDLE_ACK_CCIM0 — idle acknowledge status from ccim0 niu 0: idle acknowledge status of niu is 0 1: idle acknowledge status of niu is 1
  [14] IDLE_ACK_CENTER — idle acknowledge status from center niu 0: idle acknowledge status of niu is 0 1: idle acknowledge status of niu is 1
  [13] IDLE_ACK_PERILPM0 — idle acknowledge status from perilp m0 niu 0: idle acknowledge status of niu is 0 1: idle acknowledge status of niu is 1
  [12] IDLE_ACK_USB3 — idle acknowledge status from usb3 niu 0: idle acknowledge status of niu is 0 1: idle acknowledge status of niu is 1
  [11] IDLE_ACK_HDCP — idle acknowledge status from hdcp niu 0: idle acknowledge status of niu is 0 1: idle acknowledge status of niu is 1
  [10] IDLE_ACK_ISP1 — idle acknowledge status from isp1 niu 0: idle acknowledge status of niu is 0 1: idle acknowledge status of niu is 1
  [9] IDLE_ACK_ISP0 — idle acknowledge status from isp0 niu 0: idle acknowledge status of niu is 0 1: idle acknowledge status of niu is 1
  [8] IDLE_ACK_VOPL — idle acknowledge status from vopl niu 0: idle acknowledge status of niu is 0 1: idle acknowledge status of niu is 1
  [7] IDLE_ACK_VOPB — idle acknowledge status from vopb niu 0: idle acknowledge status of niu is 0 1: idle acknowledge status of niu is 1
  [6] IDLE_ACK_IEP — idle acknowledge status from iep niu 0: idle acknowledge status of niu is 0 1: idle acknowledge status of niu is 1
  [5] IDLE_ACK_RGA — idle acknowledge status from rga niu 0: idle acknowledge status of niu is 0 1: idle acknowledge status of niu is 1
  [4] IDLE_ACK_VDU — idle acknowledge status from vdu niu 0: idle acknowledge status of niu is 0 1: idle acknowledge status of niu is 1
  [3] IDLE_ACK_VCODEC — idle acknowledge status from vcodec niu 0: idle acknowledge status of niu is 0 1: idle acknowledge status of niu is 1
  [2] IDLE_ACK_PERIHP — idle acknowledge status from perihp niu 0: idle acknowledge status of niu is 0 1: idle acknowledge status of niu is 1
  [1] IDLE_ACK_PERILP — idle acknowledge status from perilp niu 0: idle acknowledge status of niu is 0 1: idle acknowledge status of niu is 1
  [0] IDLE_ACK_GPU — idle acknowledge status from gpu niu 0: idle acknowledge status of niu is 0 1: idle acknowledge status of niu is 1
0x6C PMU_CCI500_CON — CCI-500 low power control register
  [31:16] WRITE_ENABLE — When bit 16=1, bit 0 can be written by software . When bit 16=0, bit 0 cannot be written by software; When bit 17=1, bit 1 can be written by software . When bit 17=0, bit 1 cannot be written by software; ...... When bit 31=1, bit 15 can be written by software . When bit 31=0, bit 15 cannot be written by software;
  [7] QGATING_CCI500_CFG — CCI-500 Q-channel clock gating enable.
  [6] CLR_QREQ_CCI500 — CCI-500 Q-channel request sent by hardware.
  [5] QREQ_CCI500_CFG — CCI-500 Q-channel request sent by software.
  [4:2] PSTATE_CCI500 — CCI-500 P-channel pstate .
  [1] CLR_PREQ_CCI500 — CCI-500 P-channel request sent by hardware .
  [0] PREQ_CCI500_CFG — CCI-500 P-channel request sent by software
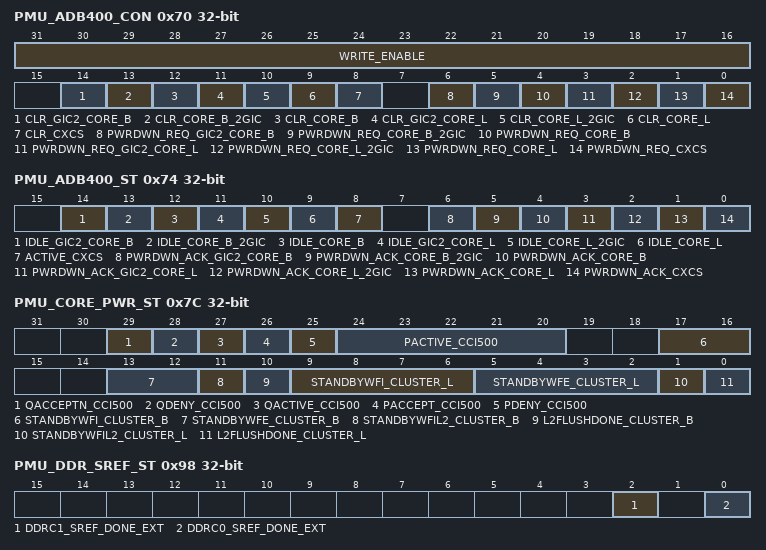
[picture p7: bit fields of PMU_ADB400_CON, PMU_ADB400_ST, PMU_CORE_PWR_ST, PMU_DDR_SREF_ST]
0x70 PMU_ADB400_CON — adb-400 low power control register
  [31:16] WRITE_ENABLE — When bit 16=1, bit 0 can be written by software . When bit 16=0, bit 0 cannot be written by software; When bit 17=1, bit 1 can be written by software . When bit 17=0, bit 1 cannot be written by software; ...... When bit 31=1, bit 15 can be written by software . When bit 31=0, bit 15 cannot be written by software;
  [14] CLR_GIC2_CORE_B — hardware send idle request to path from gic to core_b low power interface 0: disable 1: enable
  [13] CLR_CORE_B_2GIC — hardware send idle request to path from core_b to gic low power interface 0: disable 1: enable
  [12] CLR_CORE_B — hardware send idle request from core_b to cci low power interface 0: disable 1: enable
  [11] CLR_GIC2_CORE_L — hardware send idle request to path from gic to core_l low power interface 0: disable 1: enable
  [10] CLR_CORE_L_2GIC — hardware send idle request to path from core_l to gic low power interface 0: disable 1: enable
  [9] CLR_CORE_L — software send idle request from core_l to cci low power interface 0: disable 1: enable
  [8] CLR_CXCS — hardware send idle request to cxcs low power interface 0: disable 1: enable
  [6] PWRDWN_REQ_GIC2_CORE_B — send idle request to path from gic to core_b low power interface 0: disable 1: enable
  [5] PWRDWN_REQ_CORE_B_2GIC — software send idle request to path from core_b to gic low power interface 0: disable 1: enable
  [4] PWRDWN_REQ_CORE_B — software send idle request from core_b to cci low power interface 0: disable 1: enable
  [3] PWRDWN_REQ_GIC2_CORE_L — send idle request to path from gic to core_l low power interface 0: disable 1: enable
  [2] PWRDWN_REQ_CORE_L_2GIC — software send idle request to path from core_l to gic low power interface 0: disable 1: enable
  [1] PWRDWN_REQ_CORE_L — software send idle request from core_l to cci low power interface 0: disable 1: enable
  [0] PWRDWN_REQ_CXCS — software send idle request to cxcs low power interface 0: disable 1: enable
0x74 PMU_ADB400_ST access per field — adb-400 low power status register
  [14] IDLE_GIC2_CORE_B ro — active status of cxcs low power interface 0: active status is 0 (inactive) 1: active status is 1 (active)
  [13] IDLE_CORE_B_2GIC ro — active status of cxcs low power interface 0: active status is 0 (inactive) 1: active status is 1 (active)
  [12] IDLE_CORE_B ro — active status of cxcs low power interface 0: active status is 0 (inactive) 1: active status is 1 (active)
  [11] IDLE_GIC2_CORE_L wo — active status of cxcs low power interface 0: active status is 0 (inactive) 1: active status is 1 (active)
  [10] IDLE_CORE_L_2GIC ro — active status of cxcs low power interface 0: active status is 0 (inactive) 1: active status is 1 (active)
  [9] IDLE_CORE_L ro — active status of cxcs low power interface 0: active status is 0 (inactive) 1: active status is 1 (active)
  [8] ACTIVE_CXCS ro — active status of cxcs low power interface 0: active status is 0 (inactive) 1: active status is 1 (active)
  [6] PWRDWN_ACK_GIC2_CORE_B ro — idle acknowledge status from cxcs 0: idle acknowledge status of adb is 0 1: idle acknowledge status of adb is 1
  [5] PWRDWN_ACK_CORE_B_2GIC ro — idle acknowledge status from cxcs 0: idle acknowledge status of adb is 0 1: idle acknowledge status of adb is 1
  [4] PWRDWN_ACK_CORE_B ro — idle acknowledge status from cxcs 0: idle acknowledge status of adb is 0 1: idle acknowledge status of adb is 1
  [3] PWRDWN_ACK_GIC2_CORE_L ro — idle acknowledge status from cxcs 0: idle acknowledge status of adb is 0 1: idle acknowledge status of adb is 1
  [2] PWRDWN_ACK_CORE_L_2GIC ro — idle acknowledge status from cxcs 0: idle acknowledge status of adb is 0 1: idle acknowledge status of adb is 1
  [1] PWRDWN_ACK_CORE_L ro — idle acknowledge status from cxcs 0: idle acknowledge status of adb is 0 1: idle acknowledge status of adb is 1
  [0] PWRDWN_ACK_CXCS ro — idle acknowledge status from cxcs 0: idle acknowledge status of adb is 0 1: idle acknowledge status of adb is 1
0x78 PMU_POWER_ST — pmu power status register
  [6:0] POWER_STATE — power state of pmu FSM
0x7C PMU_CORE_PWR_ST ro — pmu core power status register
  [29] QACCEPTN_CCI500 — CCI-500 Q-channel accept signal, active low
  [28] QDENY_CCI500 — CCI-500 Q-channel deny signal, active high
  [27] QACTIVE_CCI500 — CCI-500 Q-channel active signal, active high
  [26] PACCEPT_CCI500 — CCI-500 P-channel accept signal, active high
  [25] PDENY_CCI500 — CCI-500 P-channel deny signal, active high
  [24:20] PACTIVE_CCI500 — CCI-500 P-channel active signal, active high
  [17:16] STANDBYWFI_CLUSTER_B — standbywfi status of cluster_b 0: cluster_b standbywfi status is 0 1: cluster_b standbywfi status is 1
  [13:12] STANDBYWFE_CLUSTER_B — standbywfe status of cluster_b 0: cluster_b standbywfe status is 0 1: cluster_b standbywfe status is 1
  [11] STANDBYWFIL2_CLUSTER_B — standbywfil2 status of cluster_b 0: cluster_b standbywfil2 status is 0 1: cluster_b standbywfil2 status is 1
  [10] L2FLUSHDONE_CLUSTER_B — l2flushdone status of cluster_b 0: cluster_b l2flushdone status is 0 1: cluster_b l2flushdone status is 1
  [9:6] STANDBYWFI_CLUSTER_L — standbywfi status of cluster_l 0: cluster_l standbywfi status is 0 1: cluster_l standbywfi status is 1
  [5:2] STANDBYWFE_CLUSTER_L — standbywfe status of cluster_l 0: cluster_l standbywfe status is 0 1: cluster_l standbywfe status is 1
  [1] STANDBYWFIL2_CLUSTER_L — standbywfil2 status of cluster_l 0: cluster_l standbywfil2 status is 0 1: cluster_l standbywfil2 status is 1
  [0] L2FLUSHDONE_CLUSTER_L — l2flushdone status of cluster_l 0: cluster_l l2flushdone status is 0 1: cluster_l l2flushdone status is 1
0x80 PMU_OSC_CNT — pmu osc count register
  [19:0] PMU_OSC_CNT — pmu osc stable counter value
0x84 PMU_PLLLOCK_CNT — pmu pll lock count register
  [19:0] PMU_PLLLOCK_CNT — pmu pll lock counter value
0x88 PMU_PLLRST_CNT — pmu pll reset count register
  [19:0] PMU_PLLRST_CNT — pmu pll reset counter value
0x8C PMU_STABLE_CNT — pmu power stable count register
  [19:0] PMU_STABLE_CNT — pmu PMIC stable counter value
0x90 PMU_DDRIO_PWRON_CNT — pmu ddrio power on count register
  [19:0] PMU_DDRIO_PWRON_CNT — pmu ddrio power on counter value
0x94 PMU_WAKEUP_RST_CLR_CNT — pmu wakeup reset clear count register
  [19:0] PMU_WAKEUP_RST_CNT — pmu wakeup reset counter value
0x98 PMU_DDR_SREF_ST — pmu ddr self refresh status register
  [2] DDRC1_SREF_DONE_EXT — ddr controller 1 self re-fresh done, active high
  [0] DDRC0_SREF_DONE_EXT — ddr controller 0 self re-fresh done, active high
0x9C PMU_SCU_L_PWRDN_CNT reset 0x5DC0 — pmu scu_l power down count register
  [19:0] PMU_SCU_L_PWRDN_CNT — pmu scu_l power down counter value
0xA0 PMU_SCU_L_PWRUP_CNT reset 0x5DC0 — pmu scu_l power up count register
  [19:0] PMU_SCU_L_PWRUP_CNT — pmu scu_l power up counter value
0xA4 PMU_SCU_B_PWRDN_CNT reset 0x5DC0 — pmu scu_b power down count register
  [19:0] PMU_SCU_B_PWRDN_CNT — pmu scu_b power down counter value
0xA8 PMU_SCU_B_PWRUP_CNT reset 0x5DC0 — pmu scu_b power up count register
  [19:0] PMU_SCU_B_PWRUP_CNT — pmu scu_b power up counter value
0xAC PMU_GPU_PWRDN_CNT reset 0x5DC0 — pmu gpu power down count register
  [19:0] PMU_GPU_PWRDN_CNT — pmu gpu power down counter value
0xB0 PMU_GPU_PWRUP_CNT reset 0x5DC0 — pmu gpu power up count register
  [19:0] PMU_GPU_PWRUP_CNT — pmu gpu power up counter value
0xB4 PMU_CENTER_PWRDN_CNT reset 0x5DC0 — pmu center power down count register
  [19:0] PMU_CENTER_PWRDN_CNT — pmu center power down counter value
0xB8 PMU_CENTER_PWRUP_CNT reset 0x5DC0 — pmu center power up count register
  [19:0] PMU_CENTER_PWRUP_CNT — pmu center power up counter value
0xBC PMU_TIMEOUT_CNT — pmu timeout count register
  [19:0] TIMEOUT_COUNT — timeout wakeup counter value
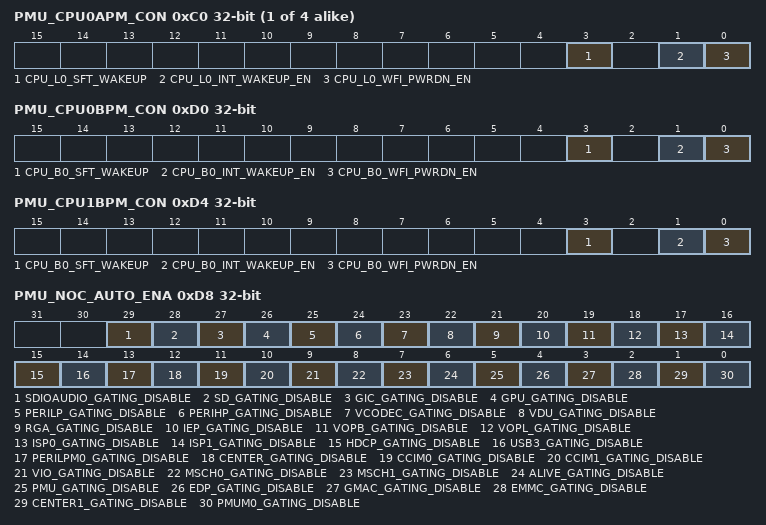
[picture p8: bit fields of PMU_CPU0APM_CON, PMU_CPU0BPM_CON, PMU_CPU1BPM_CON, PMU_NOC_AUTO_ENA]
{0xC0+4i} PMU_CPU{i}APM_CON (i=0..3) — pmu cpu{i} auto power down control register
  [3] CPU_L{i}_SFT_WAKEUP — cpu l{i} software wakeup source. 1: wakeup ; 0: nothing ;
  [1] CPU_L{i}_INT_WAKEUP_EN — cpu l{i} interrupt wake enable. 0: disable ; 1: enable ;
  [0] CPU_L{i}_WFI_PWRDN_EN — cpu_l{i} wfi power down enable. 0: disable ; 1: enable ;
0xD0 PMU_CPU0BPM_CON — pmu cluster_b cpu0 auto power down control register
  [3] CPU_B0_SFT_WAKEUP — cpu b0 software wakeup source. 1: wakeup ; 0: nothing ;
  [1] CPU_B0_INT_WAKEUP_EN — cpu b0 interrupt wake enable. 0: disable ; 1: enable ;
  [0] CPU_B0_WFI_PWRDN_EN — cpu_b0 wfi power down enable. 0: disable ; 1: enable ;
0xD4 PMU_CPU1BPM_CON — pmu cluster_b cpu0 auto power down control register
  fields as PMU_CPU0BPM_CON
0xD8 PMU_NOC_AUTO_ENA — NOC auto domain clock gating disable enable register
  [29] SDIOAUDIO_GATING_DISABLE — 0: nothing 1: clock gating disable.
  [28] SD_GATING_DISABLE — 0: nothing 1: clock gating disable.
  [27] GIC_GATING_DISABLE — 0: nothing ; 1: clock gating disable.
  [26] GPU_GATING_DISABLE — 0: nothing ; 1: clock gating disable.
  [25] PERILP_GATING_DISABLE — 0: nothing ; 1: clock gating disable.
  [24] PERIHP_GATING_DISABLE — 0: nothing ; 1: clock gating disable.
  [23] VCODEC_GATING_DISABLE — 0: nothing 1: clock gating disable.
  [22] VDU_GATING_DISABLE — 0: nothing ; 1: clock gating disable.
  [21] RGA_GATING_DISABLE — 0: nothing ; 1: clock gating disable.
  [20] IEP_GATING_DISABLE — 0: nothing ; 1: clock gating disable.
  [19] VOPB_GATING_DISABLE — 0: nothing ; 1: clock gating disable.
  [18] VOPL_GATING_DISABLE — 0: nothing ; 1: clock gating disable.
  [17] ISP0_GATING_DISABLE — 0: nothing ; 1: clock gating disable.
  [16] ISP1_GATING_DISABLE — 0: nothing ; 1: clock gating disable.
  [15] HDCP_GATING_DISABLE — 0: nothing ; 1: clock gating disable.
  [14] USB3_GATING_DISABLE — 0: nothing 1: clock gating disable.
  [13] PERILPM0_GATING_DISABLE — 0: nothing ; 1: clock gating disable.
  [12] CENTER_GATING_DISABLE — 0: noting 1: clock gating disable.
  [11] CCIM0_GATING_DISABLE — 0: nothing ; 1: clock gating disable.
  [10] CCIM1_GATING_DISABLE — 0: nothing ; 1: clock gating disable.
  [9] VIO_GATING_DISABLE — 0: nothing ; 1: clock gating disable.
  [8] MSCH0_GATING_DISABLE — 0: nothing ; 1: clock gating disable.
  [7] MSCH1_GATING_DISABLE — 0: nothing ; 1: clock gating disable.
  [6] ALIVE_GATING_DISABLE — 0: nothing ; 1: clock gating disable.
  [5] PMU_GATING_DISABLE — 0: nothing ; 1: clock gating disable.
  [4] EDP_GATING_DISABLE — 0: nothing ; 1: clock gating disable.
  [3] GMAC_GATING_DISABLE — 0: nothing ; 1: gmac clock gating disable.
  [2] EMMC_GATING_DISABLE — 0: nothing ; 1: clock gating disable.
  [1] CENTER1_GATING_DISABLE — 0: nothing 1: clock gating disable.
  [0] PMUM0_GATING_DISABLE — 0: noting ; 1: clock gating disable.
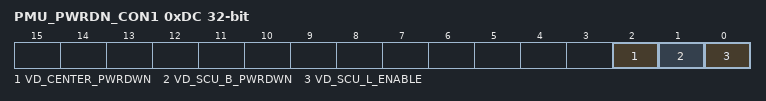
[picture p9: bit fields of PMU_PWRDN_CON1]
0xDC PMU_PWRDN_CON1 — pmu power down configure register1
  [2] VD_CENTER_PWRDWN — vd_center power down enable 0: disable 1: enable
  [1] VD_SCU_B_PWRDWN — vd_scu_b power down enable 0: disable 1: enable
  [0] VD_SCU_L_ENABLE — vd_scu_l power down enable 0: disable 1: enable
{0xF0+4i} PMU_SYS_REG{i} (i=0..3) — pmu system register {i}
  [31:0] PMU_SYS_REG{i} — system register {i}
